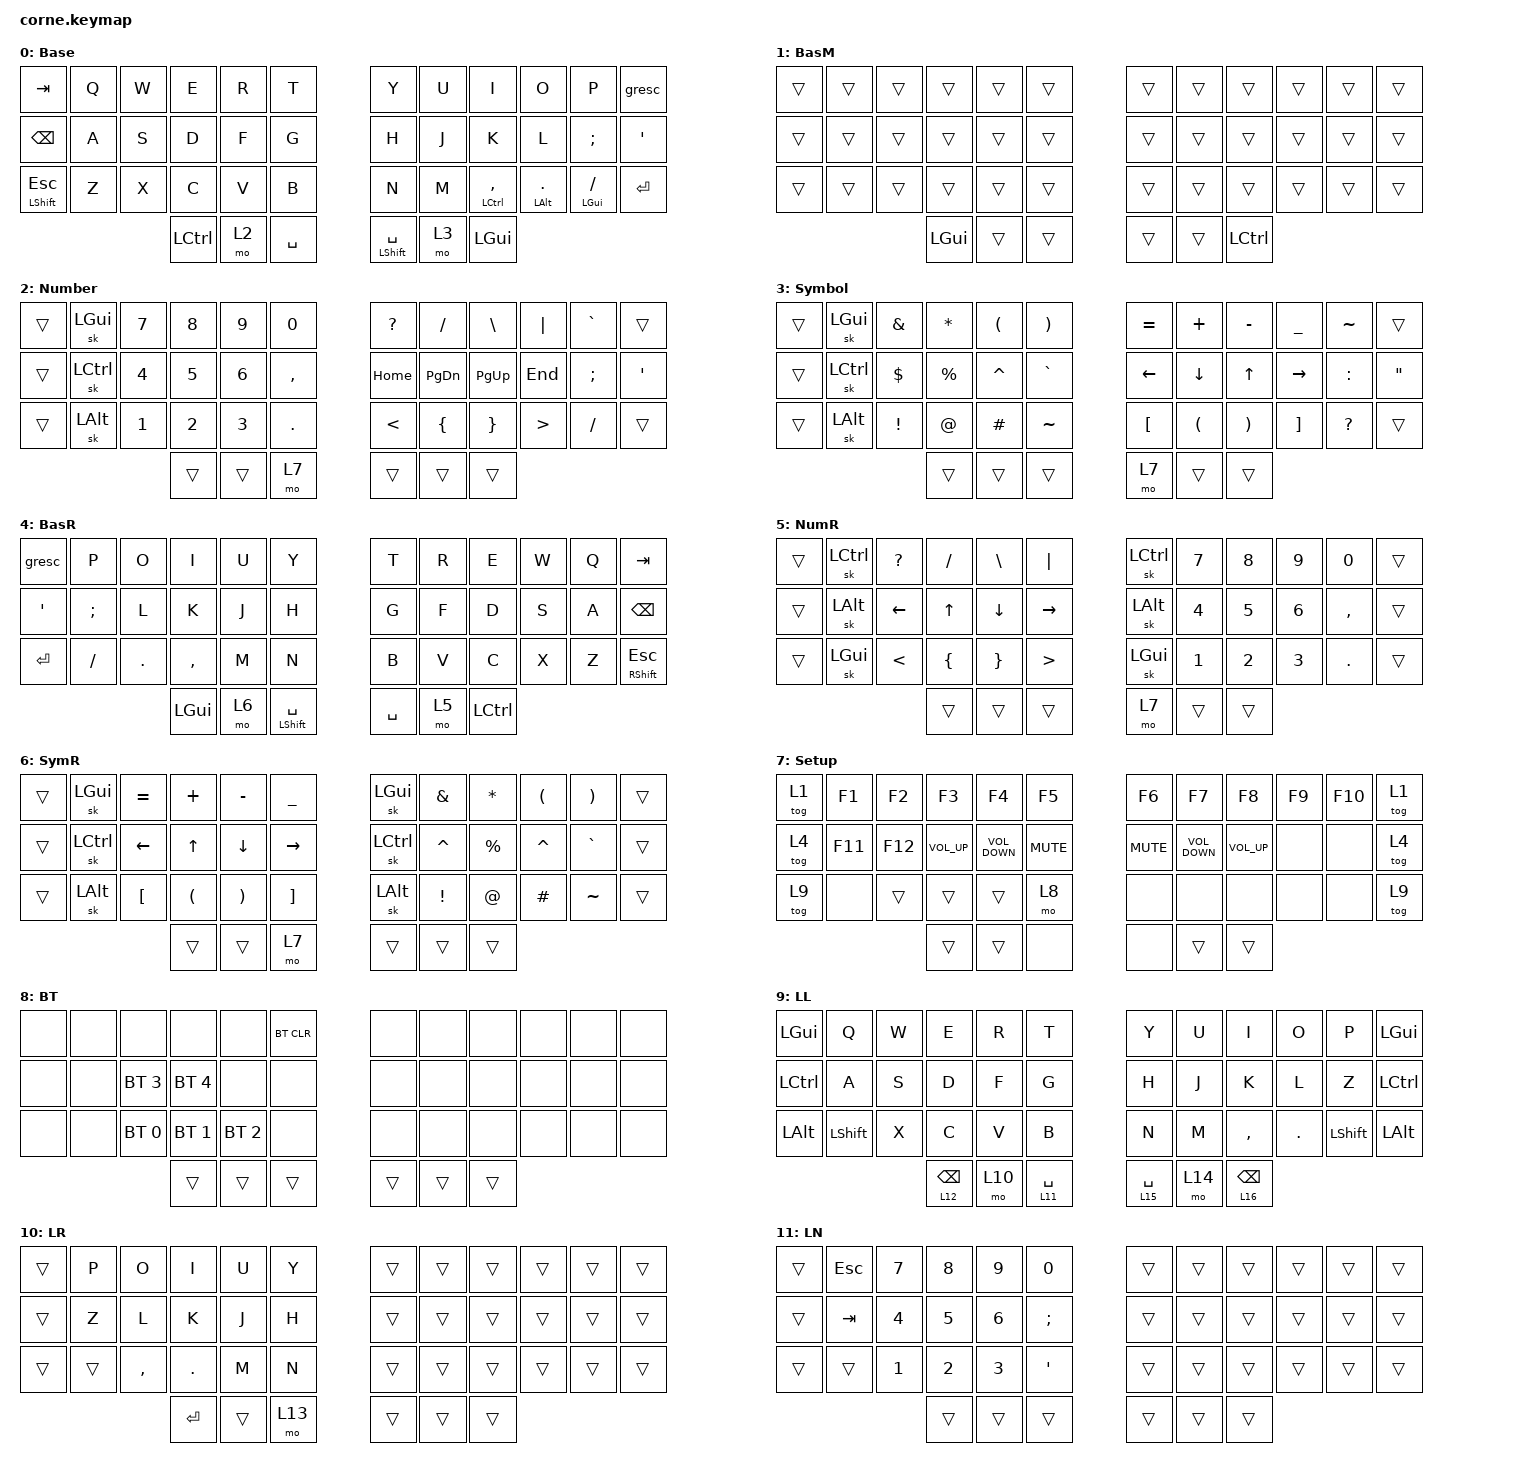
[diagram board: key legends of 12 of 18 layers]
/*
 * Copyright (c) 2020 The ZMK Contributors
 *
 * SPDX-License-Identifier: MIT
 */

#include <behaviors.dtsi>
#include <dt-bindings/zmk/bt.h>
#include <dt-bindings/zmk/keys.h>

&mt {
    flavor = "tap-preferred";
    global-quick-tap;
};

&lt {
    quick-tap-ms = <150>;
    tapping-term-ms = <300>;
};

/ {
    behaviors {
        mt_balanced: mt_balanced {
            compatible = "zmk,behavior-hold-tap";
            label = "MT_BALANCED";
            bindings = <&kp>, <&kp>;

            #binding-cells = <2>;
            tapping-term-ms = <200>;
            global-quick-tap;
            flavor = "balanced";
        };

        mt_hold: mt_hold {
            compatible = "zmk,behavior-hold-tap";
            label = "MT_HOLD";
            bindings = <&kp>, <&kp>;

            #binding-cells = <2>;
            tapping-term-ms = <200>;
            global-quick-tap;
        };
    };

    keymap {
        compatible = "zmk,keymap";

        base_layer {
            label = "Base";
            bindings = <
&kp TAB                     &kp Q  &kp W  &kp E             &kp R  &kp T        &kp Y                      &kp U  &kp I                   &kp O                &kp P               &gresc
&kp BACKSPACE               &kp A  &kp S  &kp D             &kp F  &kp G        &kp H                      &kp J  &kp K                   &kp L                &kp SEMI            &kp SQT
&mt_hold LEFT_SHIFT ESCAPE  &kp Z  &kp X  &kp C             &kp V  &kp B        &kp N                      &kp M  &mt LEFT_CONTROL COMMA  &mt LEFT_ALT PERIOD  &mt LEFT_GUI SLASH  &kp ENTER
                                          &kp LEFT_CONTROL  &mo 2  &kp SPACE    &mt_hold LEFT_SHIFT SPACE  &mo 3  &kp LEFT_GUI
            >;
        };

        base_layer_mac {
            bindings = <
&trans  &trans  &trans  &trans        &trans  &trans    &trans  &trans  &trans            &trans  &trans  &trans
&trans  &trans  &trans  &trans        &trans  &trans    &trans  &trans  &trans            &trans  &trans  &trans
&trans  &trans  &trans  &trans        &trans  &trans    &trans  &trans  &trans            &trans  &trans  &trans
                        &kp LEFT_GUI  &trans  &trans    &trans  &trans  &kp LEFT_CONTROL
            >;

            label = "BasM";
        };

        number_layer {
            label = "Number";
            bindings = <
&trans  &sk LGUI   &kp N7  &kp N8  &kp N9  &kp N0       &kp QUESTION   &kp SLASH       &kp BACKSLASH    &kp PIPE          &kp GRAVE      &trans
&trans  &sk LCTRL  &kp N4  &kp N5  &kp N6  &kp COMMA    &kp HOME       &kp PAGE_DOWN   &kp PAGE_UP      &kp END           &kp SEMICOLON  &kp SQT
&trans  &sk LALT   &kp N1  &kp N2  &kp N3  &kp DOT      &kp LESS_THAN  &kp LEFT_BRACE  &kp RIGHT_BRACE  &kp GREATER_THAN  &kp SLASH      &trans
                           &trans  &trans  &mo 7        &trans         &trans          &trans
            >;
        };

        symbol_layer {
            label = "Symbol";
            bindings = <
&trans  &sk LGUI   &kp AMPERSAND    &kp ASTERISK  &kp LEFT_PARENTHESIS  &kp RIGHT_PARENTHESIS    &kp EQUAL         &kp PLUS              &kp MINUS              &kp UNDERSCORE     &kp TILDE     &trans
&trans  &sk LCTRL  &kp DOLLAR       &kp PERCENT   &kp CARET             &kp GRAVE                &kp LEFT          &kp DOWN              &kp UP                 &kp RIGHT          &kp COLON     &kp DOUBLE_QUOTES
&trans  &sk LALT   &kp EXCLAMATION  &kp AT_SIGN   &kp HASH              &kp TILDE                &kp LEFT_BRACKET  &kp LEFT_PARENTHESIS  &kp RIGHT_PARENTHESIS  &kp RIGHT_BRACKET  &kp QUESTION  &trans
                                    &trans        &trans                &trans                   &mo 7             &trans                &trans
            >;
        };

        layer_base_reverse {
            bindings = <
&gresc   &kp P     &kp O    &kp I         &kp U  &kp Y                        &kp T      &kp R  &kp E             &kp W  &kp Q  &kp TAB
&kp SQT  &kp SEMI  &kp L    &kp K         &kp J  &kp H                        &kp G      &kp F  &kp D             &kp S  &kp A  &kp BSPC
&kp RET  &kp FSLH  &kp DOT  &kp COMMA     &kp M  &kp N                        &kp B      &kp V  &kp C             &kp X  &kp Z  &mt_hold RSHFT ESCAPE
                            &kp LEFT_GUI  &mo 6  &mt_hold LEFT_SHIFT SPACE    &kp SPACE  &mo 5  &kp LEFT_CONTROL
            >;

            label = "BasR";
        };

        layer_number_reverse {
            bindings = <
&trans  &sk LEFT_CONTROL  &kp QUESTION   &kp SLASH       &kp BACKSLASH    &kp PIPE            &sk LEFT_CONTROL  &kp N7  &kp N8  &kp N9  &kp N0     &trans
&trans  &sk LEFT_ALT      &kp LEFT       &kp UP          &kp DOWN         &kp RIGHT           &sk LEFT_ALT      &kp N4  &kp N5  &kp N6  &kp COMMA  &trans
&trans  &sk LEFT_GUI      &kp LESS_THAN  &kp LEFT_BRACE  &kp RIGHT_BRACE  &kp GREATER_THAN    &sk LEFT_GUI      &kp N1  &kp N2  &kp N3  &kp DOT    &trans
                                         &trans          &trans           &trans              &mo 7             &trans  &trans
            >;

            label = "NumR";
        };

        layer_symbol_reverse {
            bindings = <
&trans  &sk LGUI   &kp EQUAL         &kp PLUS              &kp MINUS              &kp UNDERSCORE       &sk LGUI   &kp AMPERSAND    &kp ASTERISK  &kp LEFT_PARENTHESIS  &kp RIGHT_PARENTHESIS  &trans
&trans  &sk LCTRL  &kp LEFT          &kp UP                &kp DOWN               &kp RIGHT            &sk LCTRL  &kp CARET        &kp PERCENT   &kp CARET             &kp GRAVE              &trans
&trans  &sk LALT   &kp LEFT_BRACKET  &kp LEFT_PARENTHESIS  &kp RIGHT_PARENTHESIS  &kp RIGHT_BRACKET    &sk LALT   &kp EXCLAMATION  &kp AT_SIGN   &kp HASH              &kp TILDE              &trans
                                     &trans                &trans                 &mo 7                &trans     &trans           &trans
            >;

            label = "SymR";
        };

        setup_layer {
            bindings = <
&tog 1  &kp F1   &kp F2   &kp F3           &kp F4             &kp F5        &kp F6      &kp F7             &kp F8           &kp F9  &kp F10  &tog 1
&tog 4  &kp F11  &kp F12  &kp K_VOLUME_UP  &kp K_VOLUME_DOWN  &kp K_MUTE    &kp K_MUTE  &kp K_VOLUME_DOWN  &kp K_VOLUME_UP  &none   &none    &tog 4
&tog 9  &none    &trans   &trans           &trans             &mo 8         &none       &none              &none            &none   &none    &tog 9
                          &trans           &trans             &none         &none       &trans             &trans
            >;

            label = "Setup";
        };

        layer_bt {
            bindings = <
&none  &none  &none         &none         &none         &bt BT_CLR    &none   &none   &none   &none  &none  &none
&none  &none  &bt BT_SEL 3  &bt BT_SEL 4  &none         &none         &none   &none   &none   &none  &none  &none
&none  &none  &bt BT_SEL 0  &bt BT_SEL 1  &bt BT_SEL 2  &none         &none   &none   &none   &none  &none  &none
                            &trans        &trans        &trans        &trans  &trans  &trans
            >;

            label = "BT";
        };

        layer_left {
            bindings = <
&kp LGUI          &kp Q      &kp W  &kp E             &kp R   &kp T           &kp Y         &kp U   &kp I             &kp O    &kp P           &kp LGUI
&kp LEFT_CONTROL  &kp A      &kp S  &kp D             &kp F   &kp G           &kp H         &kp J   &kp K             &kp L    &kp Z           &kp LCTRL
&kp LEFT_ALT      &kp LSHFT  &kp X  &kp C             &kp V   &kp B           &kp N         &kp M   &kp COMMA         &kp DOT  &kp LEFT_SHIFT  &kp LEFT_ALT
                                    &lt 12 BACKSPACE  &mo 10  &lt 11 SPACE    &lt 15 SPACE  &mo 14  &lt 16 BACKSPACE
            >;

            label = "LL";
        };

        layer_right {
            bindings = <
&trans  &kp P   &kp O      &kp I      &kp U   &kp Y     &trans  &trans  &trans  &trans  &trans  &trans
&trans  &kp Z   &kp L      &kp K      &kp J   &kp H     &trans  &trans  &trans  &trans  &trans  &trans
&trans  &trans  &kp COMMA  &kp DOT    &kp M   &kp N     &trans  &trans  &trans  &trans  &trans  &trans
                           &kp ENTER  &trans  &mo 13    &trans  &trans  &trans
            >;

            label = "LR";
        };

        layer_number {
            bindings = <
&trans  &kp ESCAPE  &kp N7  &kp N8  &kp N9  &kp N0           &trans  &trans  &trans  &trans  &trans  &trans
&trans  &kp TAB     &kp N4  &kp N5  &kp N6  &kp SEMICOLON    &trans  &trans  &trans  &trans  &trans  &trans
&trans  &trans      &kp N1  &kp N2  &kp N3  &kp SQT          &trans  &trans  &trans  &trans  &trans  &trans
                            &trans  &trans  &trans           &trans  &trans  &trans
            >;

            label = "LN";
        };

        layer_arrow {
            bindings = <
&trans  &kp GRAVE  &kp LEFT   &kp UP         &kp DOWN              &kp RIGHT                &trans  &trans  &trans  &trans  &trans  &trans
&trans  &kp TILDE  &kp EQUAL  &kp MINUS      &kp LEFT_PARENTHESIS  &kp RIGHT_PARENTHESIS    &trans  &trans  &trans  &trans  &trans  &trans
&trans  &trans     &kp SLASH  &kp BACKSLASH  &kp LEFT_BRACKET      &kp RIGHT_BRACKET        &trans  &trans  &trans  &trans  &trans  &trans
                              &trans         &trans                &trans                   &trans  &trans  &trans
            >;

            label = "LA";
        };

        layer_bt_1 {
            bindings = <
&none  &none  &none         &none         &none         &bt BT_CLR    &none  &none  &none  &none  &none  &none
&none  &none  &bt BT_SEL 3  &bt BT_SEL 4  &none         &none         &none  &none  &none  &none  &none  &none
&to 0  &none  &bt BT_SEL 0  &bt BT_SEL 1  &bt BT_SEL 2  &none         &none  &none  &none  &none  &none  &none
                            &trans        &trans        &trans        &none  &none  &none
            >;

            label = "LB";
        };

        layer_left_2 {
            bindings = <
&trans  &trans  &trans  &trans  &trans  &trans    &kp T   &kp R      &kp E      &kp W  &kp Q   &trans
&trans  &trans  &trans  &trans  &trans  &trans    &kp G   &kp F      &kp D      &kp S  &kp A   &trans
&trans  &trans  &trans  &trans  &trans  &trans    &kp B   &kp V      &kp C      &kp X  &trans  &trans
                        &trans  &trans  &trans    &mo 17  &kp ENTER  &kp ENTER
            >;

            label = "RL";
        };

        layer_number_2 {
            bindings = <
&trans  &trans  &trans  &trans  &trans  &trans    &kp N0         &kp N7  &kp N8  &kp N9  &kp ESCAPE  &trans
&trans  &trans  &trans  &trans  &trans  &trans    &kp SEMICOLON  &kp N4  &kp N5  &kp N6  &kp TAB     &trans
&trans  &trans  &trans  &trans  &trans  &trans    &kp SQT        &kp N1  &kp N2  &kp N3  &trans      &trans
                        &trans  &trans  &trans    &trans         &trans  &trans
            >;

            label = "RN";
        };

        layer_arrow_2 {
            bindings = <
&trans  &trans  &trans  &trans  &trans  &trans    &kp LEFT              &kp DOWN               &kp UP     &kp RIGHT      &kp GRAVE  &trans
&trans  &trans  &trans  &trans  &trans  &trans    &kp LEFT_PARENTHESIS  &kp RIGHT_PARENTHESIS  &kp EQUAL  &kp MINUS      &kp TILDE  &trans
&trans  &trans  &trans  &trans  &trans  &trans    &kp LEFT_BRACKET      &kp RIGHT_BRACKET      &kp SLASH  &kp BACKSLASH  &trans     &trans
                        &trans  &trans  &trans    &trans                &trans                 &trans
            >;

            label = "RA";
        };

        layer_bt_2 {
            bindings = <
&none  &none  &none  &none  &none  &none    &bt BT_CLR  &none         &none         &none         &none  &none
&none  &none  &none  &none  &none  &none    &none       &bt BT_SEL 3  &bt BT_SEL 4  &none         &none  &none
&none  &none  &none  &none  &none  &none    &none       &bt BT_SEL 0  &bt BT_SEL 1  &bt BT_SEL 2  &none  &to 0
                     &none  &none  &none    &trans      &trans        &trans
            >;

            label = "RB";
        };
    };
};
